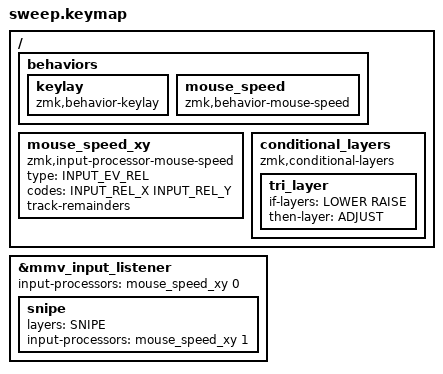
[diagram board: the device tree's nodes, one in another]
/*
 * Copyright (c) 2020 The ZMK Contributors
 *
 * SPDX-License-Identifier: MIT
 */

 /*
 references:
	https://github.com/minusfive/zmk-config/blob/main/knucklehead/combos.dtsi
	https://github.com/filterpaper/zmk-config/blob/main/config/sweep.keymap
	https://github.com/caksoylar/zmk-config/blob/main/config/combos.dtsi
 */

#include <behaviors.dtsi>
#include <dt-bindings/zmk/keys.h>
#include <dt-bindings/zmk/bt.h>
#include <dt-bindings/zmk/outputs.h>

// Mouse key speeds; these must come before pointing.h. Pointer movement runs at the speed
// level picked with &mouse_speed (src/mouse_speed.c): levels 1-3 are 1/4, 2/4 and 3/4 of
// MOVE_VAL. Scrolling always runs at SCRL_VAL, whatever the level or Snipe.
#define ZMK_POINTING_DEFAULT_MOVE_VAL	2400	// ZMK default 600
#define ZMK_POINTING_DEFAULT_SCRL_VAL	15		// ZMK default 10
#include <dt-bindings/zmk/pointing.h>
#include <input/processors.dtsi>

#define ALL		(-1)
#define NONE	0
#define DEFAULT	0
#define COLEMAK	1
#define LOWER	2
#define RAISE	3
#define ADJUST	4
#define MOUSE	5
#define TEST	6
#define SNIPE	7
#define SCROLL	8

#define ________	&trans
#define XXXXXXXX 	&none

#define FOCUS_NEXT	&kp LC(F4)
#define FOCUS_MENU	&kp LC(F2)
#define GO_BACK		&kp LG(LBKT)
#define GO_FORWARD	&kp LG(RBKT)

#define HM_LP	&hm LCTRL
#define HM_LR	&hm LGUI
#define HM_LM	&hm_alt LALT
#define HM_LI	&hm LSHFT

#define HM_RI	&hm RSHFT
#define HM_RM	&hm_alt RALT
#define HM_RR	&hm LGUI
#define HM_RP	&hm LCTRL

#define TAPPING_TERM_MS		220	// Charybdis QMK TAPPING_TERM
#define LT_TAPPING_TERM_MS	220	// TAPPING_TERM
#define TD_TAPPING_TERM_MS	220	// TAPPING_TERM
#define QUICK_TAP_MS		140	// QUICK_TAP_TERM
#define GLOBAL_QUICK_TAP_MS	150
#define IDLE_MS				150	// FLOW_TAP_TERM
#define CB_MINIMUM_SPEED	50	// COMBO_TERM (QMK default)
#define	DEFAULT_SPEED		50

#define PARAM_ZERO	0
#define PARAM_ONE	1
#define PARAM_TWO	2

#include "custom/behaviors.dtsi"
#include "custom/combos.dtsi"
#include "custom/macros.dtsi"

/ {
	behaviors {
		// The KeyLay key: opens or closes the KeyLay cheat sheet, see src/keylay.c
		keylay: keylay {
			compatible = "zmk,behavior-keylay";
			#binding-cells = <0>;
		};

		// Steps the mouse key speed level, see src/mouse_speed.c
		mouse_speed: mouse_speed {
			compatible = "zmk,behavior-mouse-speed";
			#binding-cells = <0>;
		};
	};

	mouse_speed_xy: mouse_speed_xy {
		compatible = "zmk,input-processor-mouse-speed";
		#input-processor-cells = <1>;
		type = <INPUT_EV_REL>;
		codes = <INPUT_REL_X INPUT_REL_Y>;
		track-remainders;
	};
};

#include "layer/L1-qwerty.dtsi"
#include "layer/L1-colemak.dtsi"
#include "layer/L2-lower.dtsi"
#include "layer/L3-raise.dtsi"
#include "layer/L4-adjust.dtsi"
#include "layer/L5-mouse.dtsi"
#include "layer/L6-test.dtsi"
#include "layer/L7-snipe.dtsi"
#include "layer/L8-scroll.dtsi"

// The pointer runs at the speed level picked with &mouse_speed (parameter 0). Holding Snipe on
// the Mouse layer forces the slowest level, 1, whatever level is picked.
&mmv_input_listener {
	input-processors = <&mouse_speed_xy 0>;
	snipe {
		layers = <SNIPE>;
		input-processors = <&mouse_speed_xy 1>;
	};
};

/ {
	conditional_layers {
		compatible = "zmk,conditional-layers";
		tri_layer   {
			if-layers = <LOWER RAISE>;
			then-layer = <ADJUST>;
		};
	};
};
